# TREMO register map
File version: 1.6.2
ASR6601 Cortex-M MCU
CPU: CM4 r0p1, little endian, MPU, FPU, 3 interrupt priority bits
Registers are 32-bit, read-write, reset 0x0 unless marked. A register's access mark holds for its fields unless they carry their own. Offsets are from the block's base; lines under a group give offsets from that group; [hi:lo] are bit positions; {n}, {i} and the like mark numbered series; 'fields as' and 'values as' point back to an identical list; <NAME> marks a mode.

## Memory map
0x40000000 RCC size 0x1000
0x40001000 SYSCFG size 0x400 — System configuration
0x40001800 PWR size 0x400 — Power control
0x40002000 I2S size 0x400
0x40003000 UART0 size 0x1000 — UART
0x40004000 UART1 size 0x1000 — UART
0x40005000 LPUART size 0x1000 — Low power UART
0x40006000 SSP0 size 0x1000
0x40007000 I2C0 size 0x1000
0x40008000 AFEC size 0x400
0x40009000 LORAC size 0x400
0x4000A000 TIMER0 size 0x400 — Timer
0x4000B000 TIMER2 size 0x400 — Timer
0x4000C000 BSTIMER0 size 0x400 — Basic timer
0x4000D000 LPTIMER0 size 0x400 — LPTIMER
0x4000D800 LPTIMER1 size 0x400 — LPTIMER
0x4000E000 RTC size 0x1000
0x4000F000 SEC size 0x400
0x40010000 UART2 size 0x1000 — UART
0x40011000 UART3 size 0x1000 — UART
0x40012000 SSP1 size 0x1000
0x40013000 SSP2 size 0x1000
0x40014000 I2C1 size 0x1000
0x40017000 ADC size 0x400
0x40018000 LCD size 0x400
0x40019000 DAC size 0x400
0x4001A000 TIMER1 size 0x400 — Timer
0x4001B000 TIMER3 size 0x400 — Timer
0x4001C000 BSTIMER1 size 0x400 — Basic timer
0x4001D000 IWDG size 0x400 — Independent watchdog
0x4001E000 WDG size 0x1000 — Watchdog timer
0x4001F000 GPIOA size 0x400 — GPIO
0x4001F400 GPIOB size 0x400 — GPIO
0x4001F800 GPIOC size 0x400 — GPIO
0x4001FC00 GPIOD size 0x400 — GPIO
0x40020000 EFC size 0x400
0x40021000 QSPI size 0x400
0x40022000 CRC size 0x400
0x40023000 DMAC0 size 0x400 — DMA
0x40024000 DMAC1 size 0x400 — DMA
0x40032000 SAE size 0x1000 — Security subsystem
0x40033000 RNG size 0x1000 — Random number generator
0xE000E100 NVIC size 0xF00

## Interrupts
0 SEC (SEC, SAE, RNG)
1 RTC
2 WDG
3 EFC
4 UART3
6 UART0
7 UART1
8 UART2
9 LPUART
10 SSP0
11 SSP1
12 QSPI
13 I2C0
14 I2C1
16 ADC
17 AFEC
18 SSP2
19 DMA1 (DMAC1)
20 DAC
21 LORA (LORAC)
22 GPIO (GPIOA, GPIOB, GPIOC, GPIOD)
23 TIMER0
24 TIMER1
25 TIMER2
26 TIMER3
27 BSTIMER0
28 BSTIMER1
29 LPTIMER0
31 DMA0 (DMAC0)
32 I2S
33 LCD
34 PWR
35 LPTIMER1
36 IWDG

## Further device data
name=Copyright 2022 ASRmicro, flashBaseAddress=0x08000000, flashSize=0x00020000, flashAccessTypes=rx, sramBaseAddress=0x20000000, sramSize=0x00004000, sramAccessTypes=rwx

## RCC
Base 0x40000000
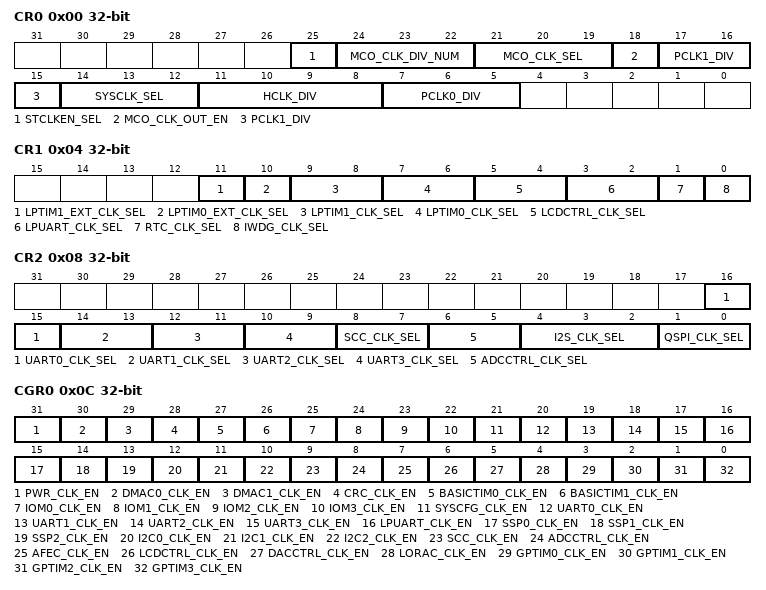
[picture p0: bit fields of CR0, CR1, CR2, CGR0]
0x00 CR0 — Control register 0
  [25] STCLKEN_SEL, [24:22] MCO_CLK_DIV_NUM, [21:19] MCO_CLK_SEL, [18] MCO_CLK_OUT_EN, [17:15] PCLK1_DIV, [14:12] SYSCLK_SEL, [11:8] HCLK_DIV, [7:5] PCLK0_DIV
0x04 CR1 — Control register 1
  [11] LPTIM1_EXT_CLK_SEL, [10] LPTIM0_EXT_CLK_SEL, [9:8] LPTIM1_CLK_SEL, [7:6] LPTIM0_CLK_SEL, [5:4] LCDCTRL_CLK_SEL, [3:2] LPUART_CLK_SEL, [1] RTC_CLK_SEL, [0] IWDG_CLK_SEL
0x08 CR2 — Control register 2
  [16-2n:15-2n] UART{n}_CLK_SEL (n=0..3), [8:7] SCC_CLK_SEL, [6:5] ADCCTRL_CLK_SEL, [4:2] I2S_CLK_SEL, [1:0] QSPI_CLK_SEL
0x0C CGR0 — clock generation register 0
  [31] PWR_CLK_EN, [30] DMAC0_CLK_EN, [29] DMAC1_CLK_EN, [28] CRC_CLK_EN, [27] BASICTIM0_CLK_EN, [26] BASICTIM1_CLK_EN, [25-n] IOM{n}_CLK_EN (n=0..3), [21] SYSCFG_CLK_EN, [20-n] UART{n}_CLK_EN (n=0..3), [16] LPUART_CLK_EN, [15] SSP0_CLK_EN, [14] SSP1_CLK_EN, [13] SSP2_CLK_EN, [12] I2C0_CLK_EN, [11] I2C1_CLK_EN, [10] I2C2_CLK_EN, [9] SCC_CLK_EN, [8] ADCCTRL_CLK_EN, [7] AFEC_CLK_EN, [6] LCDCTRL_CLK_EN, [5] DACCTRL_CLK_EN, [4] LORAC_CLK_EN, [3-n] GPTIM{n}_CLK_EN (n=0..3)
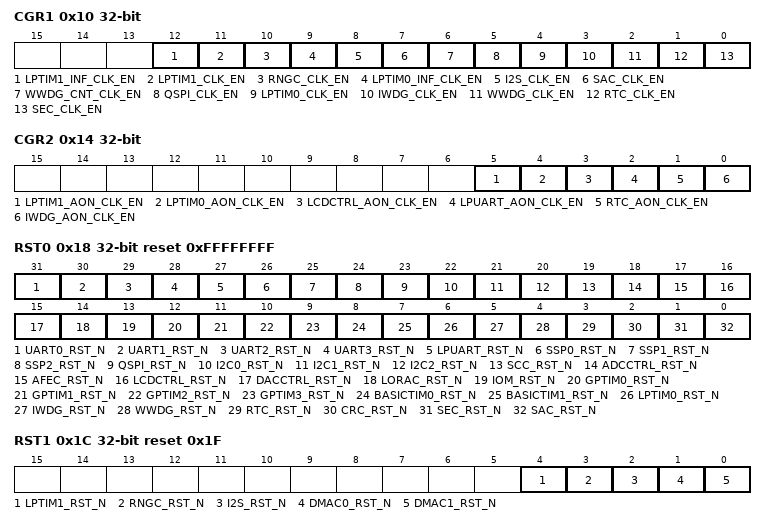
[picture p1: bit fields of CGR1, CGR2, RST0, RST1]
0x10 CGR1 — clock generation register 1
  [12] LPTIM1_INF_CLK_EN, [11] LPTIM1_CLK_EN, [10] RNGC_CLK_EN, [9] LPTIM0_INF_CLK_EN, [8] I2S_CLK_EN, [7] SAC_CLK_EN, [6] WWDG_CNT_CLK_EN, [5] QSPI_CLK_EN, [4] LPTIM0_CLK_EN, [3] IWDG_CLK_EN, [2] WWDG_CLK_EN, [1] RTC_CLK_EN, [0] SEC_CLK_EN
0x14 CGR2 — clock generation register 2
  [5] LPTIM1_AON_CLK_EN, [4] LPTIM0_AON_CLK_EN, [3] LCDCTRL_AON_CLK_EN, [2] LPUART_AON_CLK_EN, [1] RTC_AON_CLK_EN, [0] IWDG_AON_CLK_EN
0x18 RST0 reset 0xFFFFFFFF — Control register 0
  [31-n] UART{n}_RST_N (n=0..3), [27] LPUART_RST_N, [26] SSP0_RST_N, [25] SSP1_RST_N, [24] SSP2_RST_N, [23] QSPI_RST_N, [22] I2C0_RST_N, [21] I2C1_RST_N, [20] I2C2_RST_N, [19] SCC_RST_N, [18] ADCCTRL_RST_N, [17] AFEC_RST_N, [16] LCDCTRL_RST_N, [15] DACCTRL_RST_N, [14] LORAC_RST_N, [13] IOM_RST_N, [12-n] GPTIM{n}_RST_N (n=0..3), [8] BASICTIM0_RST_N, [7] BASICTIM1_RST_N, [6] LPTIM0_RST_N, [5] IWDG_RST_N, [4] WWDG_RST_N, [3] RTC_RST_N, [2] CRC_RST_N, [1] SEC_RST_N, [0] SAC_RST_N
0x1C RST1 reset 0x1F — Control register 0
  [4] LPTIM1_RST_N, [3] RNGC_RST_N, [2] I2S_RST_N, [1] DMAC0_RST_N, [0] DMAC1_RST_N
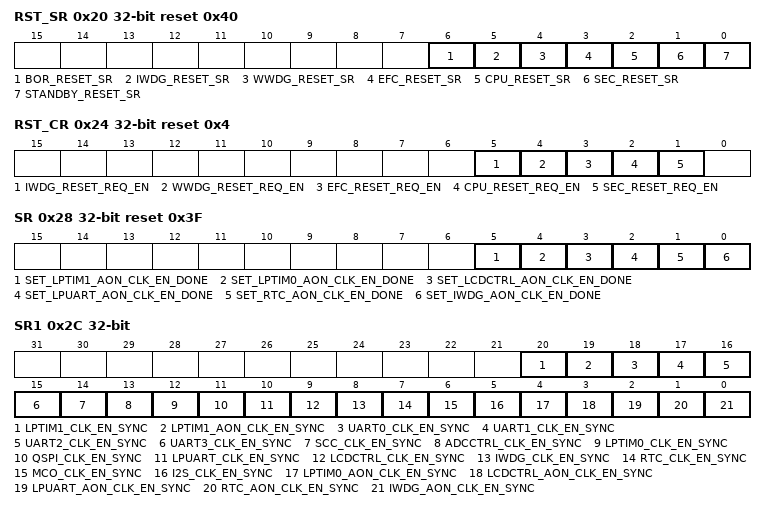
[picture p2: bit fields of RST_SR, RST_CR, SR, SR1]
0x20 RST_SR reset 0x40 — Reset status register
  [6] BOR_RESET_SR, [5] IWDG_RESET_SR, [4] WWDG_RESET_SR, [3] EFC_RESET_SR, [2] CPU_RESET_SR, [1] SEC_RESET_SR, [0] STANDBY_RESET_SR
0x24 RST_CR reset 0x4 — Reset control register
  [5] IWDG_RESET_REQ_EN, [4] WWDG_RESET_REQ_EN, [3] EFC_RESET_REQ_EN, [2] CPU_RESET_REQ_EN, [1] SEC_RESET_REQ_EN
0x28 SR ro reset 0x3F — Reset status register
  [5] SET_LPTIM1_AON_CLK_EN_DONE, [4] SET_LPTIM0_AON_CLK_EN_DONE, [3] SET_LCDCTRL_AON_CLK_EN_DONE, [2] SET_LPUART_AON_CLK_EN_DONE, [1] SET_RTC_AON_CLK_EN_DONE, [0] SET_IWDG_AON_CLK_EN_DONE
0x2C SR1 ro — Reset status register
  [20] LPTIM1_CLK_EN_SYNC, [19] LPTIM1_AON_CLK_EN_SYNC, [18-n] UART{n}_CLK_EN_SYNC (n=0..3), [14] SCC_CLK_EN_SYNC, [13] ADCCTRL_CLK_EN_SYNC, [12] LPTIM0_CLK_EN_SYNC, [11] QSPI_CLK_EN_SYNC, [10] LPUART_CLK_EN_SYNC, [9] LCDCTRL_CLK_EN_SYNC, [8] IWDG_CLK_EN_SYNC, [7] RTC_CLK_EN_SYNC, [6] MCO_CLK_EN_SYNC, [5] I2S_CLK_EN_SYNC, [4] LPTIM0_AON_CLK_EN_SYNC, [3] LCDCTRL_AON_CLK_EN_SYNC, [2] LPUART_AON_CLK_EN_SYNC, [1] RTC_AON_CLK_EN_SYNC, [0] IWDG_AON_CLK_EN_SYNC
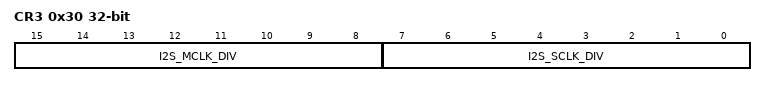
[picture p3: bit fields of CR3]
0x30 CR3 — Control register 3
  [15:8] I2S_MCLK_DIV, [7:0] I2S_SCLK_DIV

## Licence text in the file
******************************************************************************* * # License * Copyright 2022 Silicon Laboratories Inc. www.silabs.com ******************************************************************************* * * SPDX-License-Identifier: Zlib * * The licensor of this software is Silicon Laboratories Inc. * * This software is provided 'as-is', without any express or implied * warranty. In no event will the authors be held liable for any damages * arising from the use of this software. * * Permission is granted to anyone to use this software for any purpose, * including commercial applications, and to alter it and redistribute it * freely, subject to the following restrictions: * * 1. The origin of this software must not be misrepresented; you must not * claim that you wrote the original software. If you use this software * in a product, an acknowledgment in the product documentation would be * appreciated but is not required. * 2. Altered source versions must be plainly marked as such, and must not be * misrepresented as being the original software. * 3. This notice may not be removed or altered from any source distribution. * *******************************************************************************
